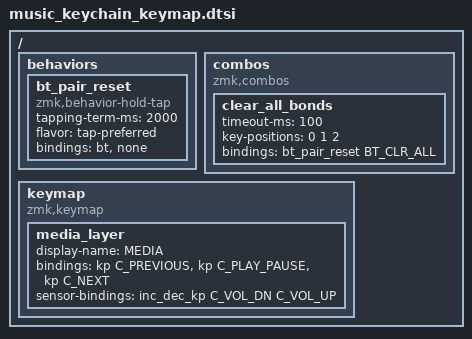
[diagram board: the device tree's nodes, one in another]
#include <behaviors.dtsi>
#include <dt-bindings/zmk/keys.h>
#include <dt-bindings/zmk/bt.h>

/ {
    behaviors {
        /*
         * A short three-button chord does nothing. Keeping the chord held for
         * two seconds invokes BT_CLR_ALL; the second parameter is consumed by
         * the no-op tap behavior.
         */
        bt_pair_reset: bt_pair_reset {
            compatible = "zmk,behavior-hold-tap";
            #binding-cells = <2>;
            tapping-term-ms = <2000>;
            flavor = "tap-preferred";
            bindings = <&bt>, <&none>;
        };
    };

    combos {
        compatible = "zmk,combos";

        clear_all_bonds {
            timeout-ms = <100>;
            key-positions = <0 1 2>;
            bindings = <&bt_pair_reset BT_CLR_ALL>;
        };
    };

    keymap {
        compatible = "zmk,keymap";

        media_layer {
            display-name = "MEDIA";
            bindings = <
                &kp C_PREVIOUS
                &kp C_PLAY_PAUSE
                &kp C_NEXT
            >;

            /* Direction corrected for the installed encoder orientation. */
            sensor-bindings = <&inc_dec_kp C_VOL_DN C_VOL_UP>;
        };
    };
};

